# STM32L151xD register map
File version: 1.0
Registers are 32-bit, read-write, reset 0x0 unless marked. A register's access mark holds for its fields unless they carry their own. Offsets are from the block's base; [hi:lo] are bit positions; {n}, {i} and the like mark numbered series.

## RI — Routing Interface
Base 0x40007C04
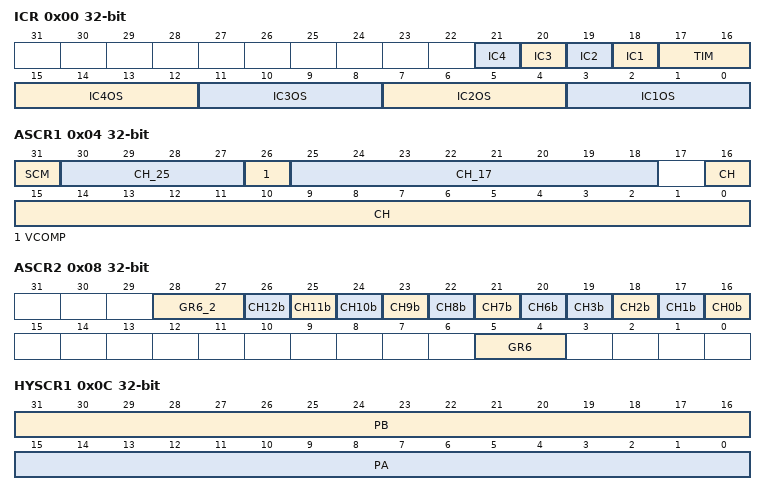
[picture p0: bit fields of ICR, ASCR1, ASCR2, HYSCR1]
0x00 ICR — RI input capture register
  [n+17] IC{n} (n=1..4) — Input capture {n}
  [17:16] TIM — TIM[3:0] bits (Timers select bits)
  [4n-1:4n-4] IC{n}OS (n=1..4) — IC{n}OS[3:0] bits (Input Capture {n} select bits)
0x04 ASCR1 — RI analog switches control register
  [31] SCM — I/O Switch control mode
  [30:27] CH_25 — AS_CH[25:18] & AS_CH[15:0] bits ( Analog switches selection bits)
  [26] VCOMP — ADC analog switch selection for internal node to COMP1
  [25:18] CH_17 — AS_CH[25:18] & AS_CH[15:0] bits ( Analog switches selection bits)
  [16:0] CH — AS_CH[25:18] & AS_CH[15:0] bits ( Analog switches selection bits)
0x08 ASCR2 — RI analog switch control register 2
  [28:27] GR6_2 — GR6 selection bits
  [n+14] CH{n}b (n=6..12) — CH{n}b selection bit
  [n+16] CH{n}b (n=0..3) — CH{n}b selection bit
  [5:4] GR6 — GR6 selection bits
0x0C HYSCR1 — RI hysteresis control register
  [31:16] PB — PB[15:0] Port B Hysteresis selection
  [15:0] PA — PA[15:0] Port A Hysteresis selection
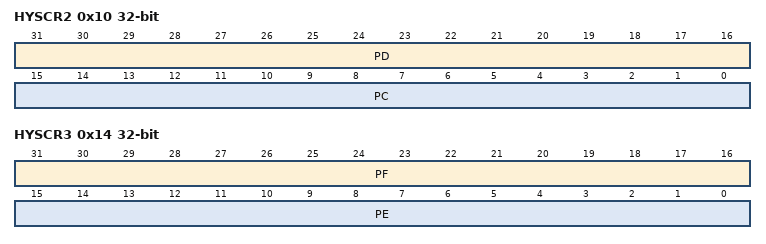
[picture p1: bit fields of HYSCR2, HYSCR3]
0x10 HYSCR2 — RI Hysteresis control register
  [31:16] PD — PD[15:0] Port D Hysteresis selection
  [15:0] PC — PC[15:0] Port C Hysteresis selection
0x14 HYSCR3 — RI Hysteresis control register
  [31:16] PF — PF[15:0] Port F Hysteresis selection
  [15:0] PE — PE[15:0] Port E Hysteresis selection
0x18 HYSCR4 — RI Hysteresis control register
  [15:0] PG — PG[15:0] Port G Hysteresis selection
0x1C ASMR1 — RI Analog switch mode register 1
  [15:0] PA — PA[15:0] Port A selection
0x20 CMR1 — RI Channel mask register 1
  [15:0] PA — PA[15:0] Port A selection
0x24 CICR1 — RI Channel Iden for capture register 1
  [15:0] PA — PA[15:0] Port A selection
0x28 ASMR2 — RI Analog switch mode register 2
  [15:0] PB — PB[15:0] Port B selection
0x2C CMR2 — RI Channel mask register 2
  [15:0] PB — PB[15:0] Port B selection
0x30 CICR2 — RI Channel Iden for capture register 2
  [15:0] PB — PB[15:0] Port B selection
0x34 ASMR3 — RI Analog switch mode register 3
  [15:0] PC — PC[15:0] Port C selection
0x38 CMR3 — RI Channel mask register 3
  [15:0] PC — PC[15:0] Port C selection
0x3C CICR3 — RI Channel Iden for capture register 3
  [15:0] PC — PC[15:0] Port C selection
0x40 ASMR4 — RI Analog switch mode register 4
  [15:0] PF — PF[15:0] Port F selection
0x44 CMR4 — RI Channel mask register 4
  [15:0] PF — PF[15:0] Port F selection
0x48 CICR4 — RI Channel Iden for capture register 4
  [15:0] PF — PF[15:0] Port F selection
0x4C ASMR5 — RI Analog switch mode register 5
  [15:0] PG — PG[15:0] Port G selection
0x50 CMR5 — RI Channel mask register 5
  [15:0] PG — PG[15:0] Port G selection
0x54 CICR5 — RI Channel Iden for capture register 5
  [15:0] PG — PG[15:0] Port G selection

## OPAMP — Operational Amplifier (OPAMP)
Base 0x40007C5C
Same registers: OPAMP1 0x40007C5C (alternate view of OPAMP), OPAMP2 0x40007C5D, OPAMP3 0x40007C5E
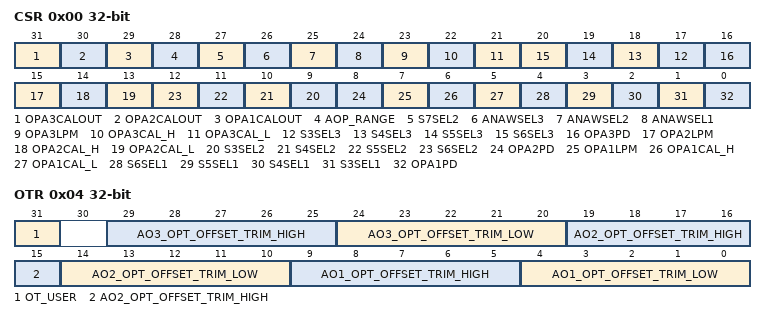
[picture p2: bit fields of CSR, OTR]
0x00 CSR — OPAMP control and status register
  [31] OPA3CALOUT — OPAMP3 calibration output
  [30] OPA2CALOUT — OPAMP2 calibration output
  [29] OPA1CALOUT — OPAMP1 calibration output
  [28] AOP_RANGE — Common to several OPAMP instances: Operational amplifier voltage supply range. Bit intended to be used with OPAMP common instance (OPAMP_Common_TypeDef)
    0=LOW (Power supply range low. On STM32L1 series: Vdda lower than 2.4V.); 1=HIGH (Power supply range high. On STM32L1 series: Vdda higher than 2.4V.)
  [27] S7SEL2 — Switch 7 for OPAMP2 Enable
  [26] ANAWSEL3 — Switch ANA Enable for OPAMP3
  [25] ANAWSEL2 — Switch ANA Enable for OPAMP2
  [24] ANAWSEL1 — Switch ANA Enable for OPAMP1
  [23] OPA3LPM — OPAMP3 Low power enable
  [22] OPA3CAL_H — OPAMP3 Offset calibration for N differential pair
  [21] OPA3CAL_L — OPAMP3 Offset calibration for P differential pair
  [n+14] S{n}SEL3 (n=3..6) — Switch {n} for OPAMP3 Enable
  [16] OPA3PD — OPAMP3 disable
  [15] OPA2LPM — OPAMP2 Low power enable
  [14] OPA2CAL_H — OPAMP2 Offset calibration for N differential pair
  [13] OPA2CAL_L — OPAMP2 Offset calibration for P differential pair
  [n+6] S{n}SEL2 (n=3..6) — Switch {n} for OPAMP2 Enable
  [8] OPA2PD — OPAMP2 disable
  [7] OPA1LPM — OPAMP1 Low power enable
  [6] OPA1CAL_H — OPAMP1 Offset calibration for N differential pair
  [5] OPA1CAL_L — OPAMP1 Offset calibration for P differential pair
  [4] S6SEL1 — Switch 6 for OPAMP1 Enable
  [3] S5SEL1 — Switch 5 for OPAMP1 Enable
  [2] S4SEL1 — Switch 4 for OPAMP1 Enable
  [1] S3SEL1 — Switch 3 for OPAMP1 Enable
    0=STANDALONE (OPAMP functional mode, OPAMP operation in standalone (on STM32L1 series, it corresponds to OPAMP internal switches S3 opened (switch SanB state depends on switch S4 state))); 1=FOLLOWER (OPAMP functional mode, OPAMP operation in follower (on STM32L1 series, it corresponds to OPAMP internal switches S3 and SanB closed))
  [0] OPA1PD — OPAMP1 disable
0x04 OTR — OPAMP
  [31] OT_USER — Switch to OPAMP offset user trimmed values
    0=FACTORY (OPAMP trimming factors set to factory values); 1=USER (OPAMP trimming factors set to user values)
  [29:25] AO3_OPT_OFFSET_TRIM_HIGH — Offset trim for transistors differential pair NMOS of OPAMP3
  [24:20] AO3_OPT_OFFSET_TRIM_LOW — Offset trim for transistors differential pair PMOS of OPAMP3
  [19:15] AO2_OPT_OFFSET_TRIM_HIGH — Offset trim for transistors differential pair NMOS of OPAMP2
  [14:10] AO2_OPT_OFFSET_TRIM_LOW — Offset trim for transistors differential pair PMOS of OPAMP2
  [9:5] AO1_OPT_OFFSET_TRIM_HIGH — Offset trim for transistors differential pair NMOS of OPAMP1
  [4:0] AO1_OPT_OFFSET_TRIM_LOW — Offset trim for transistors differential pair PMOS of OPAMP1
0x08 LPOTR — OPAMP
